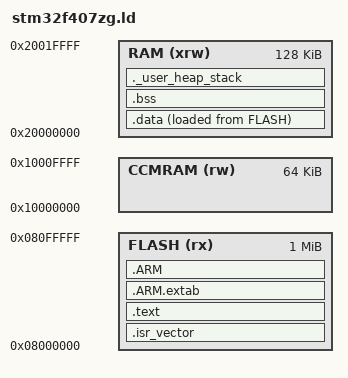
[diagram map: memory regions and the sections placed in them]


ENTRY(Reset_Handler)

MEMORY
{
  FLASH  (rx)  : ORIGIN = 0x08000000, LENGTH = 1024K
  RAM    (xrw) : ORIGIN = 0x20000000, LENGTH = 128K
  CCMRAM (rw)  : ORIGIN = 0x10000000, LENGTH = 64K
}

_estack = ORIGIN(RAM) + LENGTH(RAM);
_sstack = _estack;

SECTIONS
{
  .isr_vector :
  {
    . = ALIGN(4);
    KEEP(*(.isr_vector))
    . = ALIGN(4);
  } >FLASH

  .text :
  {
    . = ALIGN(4);
    *(.text)
    *(.text*)
    *(.rodata)
    *(.rodata*)
    *(.glue_7)
    *(.glue_7t)
    . = ALIGN(4);
    _etext = .;
  } >FLASH

  .ARM.extab :
  {
    *(.ARM.extab* .gnu.linkonce.armextab.*)
  } >FLASH

  .ARM :
  {
    __exidx_start = .;
    *(.ARM.exidx*)
    __exidx_end = .;
  } >FLASH

  _sidata = LOADADDR(.data);

  .data :
  {
    . = ALIGN(4);
    _sdata = .;
    *(.data)
    *(.data*)
    . = ALIGN(4);
    _edata = .;
  } >RAM AT> FLASH

  .bss :
  {
    . = ALIGN(4);
    _sbss = .;
    *(.bss)
    *(.bss*)
    *(COMMON)
    . = ALIGN(4);
    _ebss = .;
  } >RAM

  ._user_heap_stack :
  {
    . = ALIGN(8);
    PROVIDE(end = .);
    PROVIDE(_end = .);
    . = . + 0x800;
    . = ALIGN(8);
  } >RAM
}
